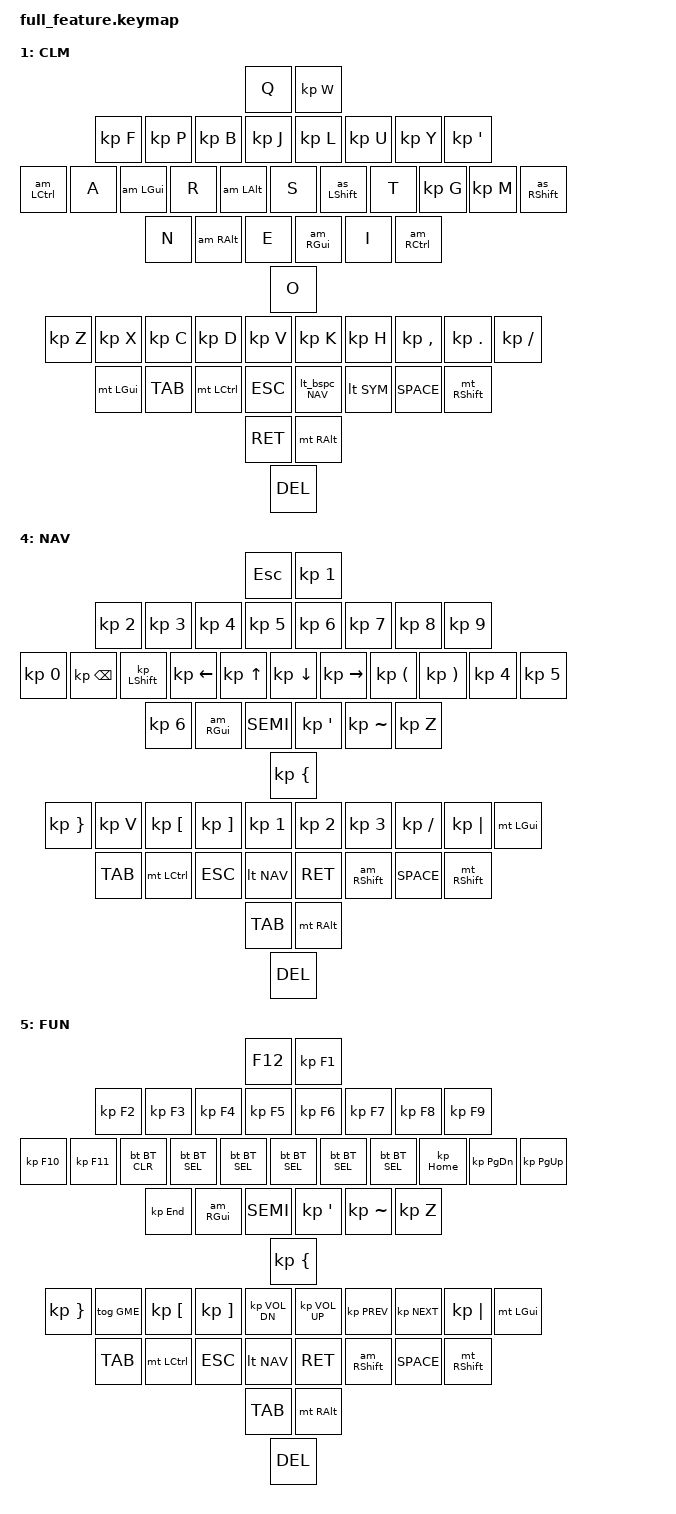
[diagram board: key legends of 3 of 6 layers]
#include <behaviors.dtsi>
#include <dt-bindings/zmk/bt.h>
#include <dt-bindings/zmk/keys.h>
#include <dt-bindings/zmk/outputs.h>
#ifdef EXTERNAL_POWER
#include <dt-bindings/zmk/ext_power.h>
#endif

// Layer aliases
#define DEF 0
#define CLM 1
#define GME 2
#define SYM 3
#define NAV 4
#define FUN 5

/* #include "combos.dtsi" */

#define THREE_THUMBS

&mt {
  flavor = "hold-preferred";
  tapping - term - ms = <190>;
};

&lt {
  flavor = "balanced";
  tapping - term - ms = <190>;
};

/ {
  behaviors {
  am:
    alpha_mods {
      compatible = "zmk,behavior-hold-tap";
      label = "ALPHA_MT";
#binding - cells = < 2>;
      tapping - term - ms = <190>;
      quick - tap - ms = <140>;
      flavor = "tap-preferred";
      bindings = <&kp>, <&kp>;
    };
  as:
    alpha_shift {
      compatible = "zmk,behavior-hold-tap";
      label = "ALPHA_SFT";
#binding - cells = < 2>;
      tapping - term - ms = <190>;
      quick - tap - ms = <140>;
      flavor = "tap-preferred";
      bindings = <&kp>, <&kp>;
    };

  // Easy alt-tab with alt+backspace thumb using mod-morphs
  bstab:
    backspace_tab {
      compatible = "zmk,behavior-mod-morph";
      label = "BSPC_TAB";
#binding - cells = < 0>;
      bindings = <&kp BSPC>, <&kp TAB>;
      mods = <MOD_LALT>;
    };
  lt_bspc:
    layer_tap_backspace_tab {
      compatible = "zmk,behavior-hold-tap";
      label = "LT_BT";
#binding - cells = < 2>;
      tapping - term - ms = <150>;
      flavor = "balanced";
      bindings = <&mo>, <&bstab>;
    };
  };

  cond_layers {
    compatible = "zmk,conditional-layers";
    // Define FUN layer as tri-state
    func_tristate {
      if
        -layers = <NAV SYM>;
      then - layer = <FUN>;
    };
  };

  keymap {
    compatible = "zmk,keymap";

    default_layer {
      label = "DEF";
      bindings =
          <
              // ╭─────────────┬─────────────┬─────────────┬─────────────┬─────────────┬─────────────╮
              // ╭─────────────┬─────────────┬─────────────┬─────────────┬─────────────┬─────────────╮
              &kp ESC &
          kp Q & kp W & kp E & kp R & kp T & kp Y & kp U & kp I & kp O & kp P &
          kp BSPC
          // ├─────────────┼─────────────┼─────────────┼─────────────┼─────────────┼─────────────┤
          // ├─────────────┼─────────────┼─────────────┼─────────────┼─────────────┼─────────────┤
          & kp LSHIFT & am LGUI A & am LALT S & am LSHIFT D & am LCTRL F &
          kp G & kp H & am RCTRL J & am RSHIFT K & am RALT L & am RGUI SEMI &
          kp SQT
          // ├─────────────┼─────────────┼─────────────┼─────────────┼─────────────┼─────────────┤
          // ├─────────────┼─────────────┼─────────────┼─────────────┼─────────────┼─────────────┤
          & kp TILDE & kp Z & kp X & kp C & kp V & kp B & kp N & kp M &
          kp COMMA & kp DOT & kp SLASH & kp PIPE
// ╰─────────────┴─────────────┴─────────────┴─────────────┼─────────────┼─────────────┤
// ├─────────────┼─────────────┼─────────────┼─────────────┴─────────────┴─────────────╯
#ifdef THREE_THUMBS
          & lt LGUI FUN & mt LCTRL ESC & lt NAV RET & lt SYM SPACE &
          mt RSHFT TAB &
          mt RALT DEL
#else
          & mt LCTRL ESC & lt NAV RET & lt SYM SPACE &
          mt RSHFT TAB
#endif
              //                                                         ╰─────────────┴─────────────╯
              //                                                         ╰─────────────┴─────────────╯
              > ;
    };

    colemak_layer {
      label = "CLM";
      bindings =
          <
              // ╭─────────────┬─────────────┬─────────────┬─────────────┬─────────────╮
              // ╭─────────────┬─────────────┬─────────────┬─────────────┬─────────────╮
              &kp Q &
          kp W & kp F & kp P & kp B & kp J & kp L & kp U & kp Y &
          kp SQT
          // ├─────────────┼─────────────┼─────────────┼─────────────┼─────────────┤
          // ├─────────────┼─────────────┼─────────────┼─────────────┼─────────────┤
          & am LCTRL A & am LGUI R & am LALT S & as LSHFT T & kp G & kp M &
          as RSHFT N & am RALT E & am RGUI I &
          am RCTRL O
          // ├─────────────┼─────────────┼─────────────┼─────────────┼─────────────┤
          // ├─────────────┼─────────────┼─────────────┼─────────────┼─────────────┤
          & kp Z & kp X & kp C & kp D & kp V & kp K & kp H & kp COMMA & kp DOT &
          kp SLASH
// ╰─────────────┴─────────────┴─────────────┼─────────────┼─────────────┤
// ├─────────────┼─────────────┼─────────────┴─────────────┴─────────────╯
#ifdef THREE_THUMBS
          & mt LGUI TAB & mt LCTRL ESC & lt_bspc NAV 0 & lt SYM SPACE &
          mt RSHFT RET &
          mt RALT DEL
#else
          & mt LCTRL ESC & lt_bspc NAV 0 & lt SYM SPACE &
          mt RSHFT RET
#endif
              //                                           ╰─────────────┴─────────────╯
              //                                           ╰─────────────┴─────────────╯
              > ;
    };

    game_layer {
      label = "GME";
      bindings =
          <
              // ╭─────────────┬─────────────┬─────────────┬─────────────┬─────────────╮
              // ╭─────────────┬─────────────┬─────────────┬─────────────┬─────────────╮
              &kp TAB &
          kp Q & kp W & kp E & kp R & kp Y & kp U & kp I & kp O &
          kp P
          // ├─────────────┼─────────────┼─────────────┼─────────────┼─────────────┤
          // ├─────────────┼─────────────┼─────────────┼─────────────┼─────────────┤
          & kp ESC & kp A & kp S & kp D & kp F & kp H & kp J & kp K & kp L &
          tog GME
          // ├─────────────┼─────────────┼─────────────┼─────────────┼─────────────┤
          // ├─────────────┼─────────────┼─────────────┼─────────────┼─────────────┤
          & kp LSHFT & kp Z & kp X & kp C & kp V & kp N & kp M & kp COMMA &
          kp DOT & kp SLASH
// ╰─────────────┴─────────────┴─────────────┼─────────────┼─────────────┤
// ├─────────────┼─────────────┼─────────────┴─────────────┴─────────────╯
#ifdef THREE_THUMBS
          & kp LCTRL & kp LALT & kp SPACE & mo NAV & kp RET &
          tog GME
#else
          & kp LALT & kp SPACE & mo NAV &
          kp RET
#endif
              //                                           ╰─────────────┴─────────────╯
              //                                           ╰─────────────┴─────────────╯
              > ;
    };

    symbol_layer {
      label = "SYM";
      bindings =
          <
              // ╭─────────────┬─────────────┬─────────────┬─────────────┬─────────────┬─────────────╮
              // ╭─────────────┬─────────────┬─────────────┬─────────────┬─────────────┬─────────────╮
              &kp TAB &
          kp EXCL & kp AT & kp HASH & kp DLLR & kp PRCNT & kp CARET & kp AMPS &
          kp KP_MULTIPLY & kp LPAR & kp RPAR &
          kp BSPC
          // ├─────────────┼─────────────┼─────────────┼─────────────┼─────────────┼─────────────┤
          // ├─────────────┼─────────────┼─────────────┼─────────────┼─────────────┼─────────────┤
          & kp GRAVE & kp BSLH & kp LBKT & kp RBKT & kp EQUAL & kp MINUS &
          kp MINUS & kp EQUAL & kp LBKT & kp RBKT & kp BSLH &
          kp GRAVE
          // ├─────────────┼─────────────┼─────────────┼─────────────┼─────────────┼─────────────┤
          // ├─────────────┼─────────────┼─────────────┼─────────────┼─────────────┼─────────────┤
          & kp TILDE & kp PIPE & kp LBRC & kp RBRC & kp PLUS & kp UNDER &
          kp UNDER & kp PLUS & kp LBRC & kp RBRC & kp PIPE & kp TILDE
// ╰─────────────┴─────────────┴─────────────┴─────────────┼─────────────┼─────────────┤
// ├─────────────┼─────────────┼─────────────┼─────────────┴─────────────┴─────────────╯
#ifdef THREE_THUMBS
          & mt LGUI TAB & mt LCTRL ESC & lt NAV RET & am RSHFT SPACE &
          mt RSHFT TAB &
          mt RALT DEL
#else
          & mt LCTRL ESC & lt NAV RET & lt SYM SPACE &
          mt RSHFT TAB
#endif
              //                                                         ╰─────────────┴─────────────╯
              //                                                         ╰─────────────┴─────────────╯
              > ;
    };

    nav_layer {
      label = "NAV";
      bindings =
          <
              // ╭─────────────┬─────────────┬─────────────┬─────────────┬─────────────┬─────────────╮
              // ╭─────────────┬─────────────┬─────────────┬─────────────┬─────────────┬─────────────╮
              &kp ESC &
          kp N1 & kp N2 & kp N3 & kp N4 & kp N5 & kp N6 & kp N7 & kp N8 &
          kp N9 & kp N0 &
          kp BSPC
          // ├─────────────┼─────────────┼─────────────┼─────────────┼─────────────┼─────────────┤
          // ├─────────────┼─────────────┼─────────────┼─────────────┼─────────────┼─────────────┤
          & kp LSHIFT & kp LEFT & kp UP & kp DOWN & kp RIGHT & kp LPAR &
          kp RPAR & kp N4 & kp N5 & kp N6 & am RGUI SEMI &
          kp SQT
          // ├─────────────┼─────────────┼─────────────┼─────────────┼─────────────┼─────────────┤
          // ├─────────────┼─────────────┼─────────────┼─────────────┼─────────────┼─────────────┤
          & kp TILDE & kp Z & kp LBRC & kp RBRC & kp V & kp LBKT & kp RBKT &
          kp N1 & kp N2 & kp N3 & kp SLASH & kp PIPE
// ╰─────────────┴─────────────┴─────────────┴─────────────┼─────────────┼─────────────┤
// ├─────────────┼─────────────┼─────────────┼─────────────┴─────────────┴─────────────╯
#ifdef THREE_THUMBS
          & mt LGUI TAB & mt LCTRL ESC & lt NAV RET & am RSHFT SPACE &
          mt RSHFT TAB &
          mt RALT DEL
#else
          & mt LCTRL ESC & lt NAV RET & lt SYM SPACE &
          mt RSHFT TAB
#endif
              //                                                         ╰─────────────┴─────────────╯
              //                                                         ╰─────────────┴─────────────╯
              > ;
    };

    function_layer {
      label = "FUN";
      bindings =
          <
              // ╭─────────────┬─────────────┬─────────────┬─────────────┬─────────────┬─────────────╮
              // ╭─────────────┬─────────────┬─────────────┬─────────────┬─────────────┬─────────────╮
              &kp F12 &
          kp F1 & kp F2 & kp F3 & kp F4 & kp F5 & kp F6 & kp F7 & kp F8 &
          kp F9 & kp F10 &
          kp F11
          // ├─────────────┼─────────────┼─────────────┼─────────────┼─────────────┼─────────────┤
          // ├─────────────┼─────────────┼─────────────┼─────────────┼─────────────┼─────────────┤
          & bt BT_CLR & bt BT_SEL 0 & bt BT_SEL 1 & bt BT_SEL 2 & bt BT_SEL 3 &
          bt BT_SEL 4 & kp HOME & kp PG_DN & kp PG_UP & kp END & am RGUI SEMI &
          kp SQT
          // ├─────────────┼─────────────┼─────────────┼─────────────┼─────────────┼─────────────┤
          // ├─────────────┼─────────────┼─────────────┼─────────────┼─────────────┼─────────────┤
          & kp TILDE & kp Z & kp LBRC & kp RBRC & tog GME & kp LBKT & kp RBKT &
          kp C_VOL_DN & kp C_VOL_UP & kp C_PREV & kp C_NEXT & kp PIPE
// ╰─────────────┴─────────────┴─────────────┴─────────────┼─────────────┼─────────────┤
// ├─────────────┼─────────────┼─────────────┼─────────────┴─────────────┴─────────────╯
#ifdef THREE_THUMBS
          & mt LGUI TAB & mt LCTRL ESC & lt NAV RET & am RSHFT SPACE &
          mt RSHFT TAB &
          mt RALT DEL
#else
          & mt LCTRL ESC & lt NAV RET & lt SYM SPACE &
          mt RSHFT TAB
#endif
              //                                                         ╰─────────────┴─────────────╯
              //                                                         ╰─────────────┴─────────────╯
              > ;
    };
  };
};
